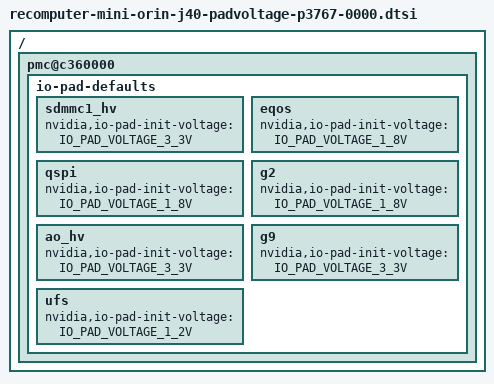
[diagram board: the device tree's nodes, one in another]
/*This dtsi file was generated by recomputer-mini-orin-j40.xlsm Revision: 1.04 */
/*
 * SPDX-FileCopyrightText: Copyright (c) 2022 NVIDIA CORPORATION & AFFILIATES. All rights reserved.
 * SPDX-License-Identifier: BSD-3-Clause
 *
 * Redistribution and use in source and binary forms, with or without
 * modification, are permitted provided that the following conditions are met:
 *
 * 1. Redistributions of source code must retain the above copyright notice, this
 * list of conditions and the following disclaimer.
 *
 * 2. Redistributions in binary form must reproduce the above copyright notice,
 * this list of conditions and the following disclaimer in the documentation
 * and/or other materials provided with the distribution.
 * 
 * 3. Neither the name of the copyright holder nor the names of its
 * contributors may be used to endorse or promote products derived from
 * this software without specific prior written permission.
 *
 * THIS SOFTWARE IS PROVIDED BY THE COPYRIGHT HOLDERS AND CONTRIBUTORS 'AS IS'
 * AND ANY EXPRESS OR IMPLIED WARRANTIES, INCLUDING, BUT NOT LIMITED TO, THE
 * IMPLIED WARRANTIES OF MERCHANTABILITY AND FITNESS FOR A PARTICULAR PURPOSE ARE
 * DISCLAIMED. IN NO EVENT SHALL THE COPYRIGHT HOLDER OR CONTRIBUTORS BE LIABLE
 * FOR ANY DIRECT, INDIRECT, INCIDENTAL, SPECIAL, EXEMPLARY, OR CONSEQUENTIAL
 * DAMAGES (INCLUDING, BUT NOT LIMITED TO, PROCUREMENT OF SUBSTITUTE GOODS OR
 * SERVICES; LOSS OF USE, DATA, OR PROFITS; OR BUSINESS INTERRUPTION) HOWEVER
 * CAUSED AND ON ANY THEORY OF LIABILITY, WHETHER IN CONTRACT, STRICT LIABILITY,
 * OR TORT (INCLUDING NEGLIGENCE OR OTHERWISE) ARISING IN ANY WAY OUT OF THE USE
 * OF THIS SOFTWARE, EVEN IF ADVISED OF THE POSSIBILITY OF SUCH DAMAGE.
 */

		#define IO_PAD_VOLTAGE_1_2V 1200000
		#define IO_PAD_VOLTAGE_1_8V 1800000
		#define IO_PAD_VOLTAGE_3_3V 3300000
/dts-v1/;
/ {
	pmc@c360000 {
		io-pad-defaults {
			sdmmc1_hv {
				nvidia,io-pad-init-voltage = <IO_PAD_VOLTAGE_3_3V>;
			};

			eqos {
				nvidia,io-pad-init-voltage = <IO_PAD_VOLTAGE_1_8V>;
			};

			qspi {
				nvidia,io-pad-init-voltage = <IO_PAD_VOLTAGE_1_8V>;
			};

			g2 {
				nvidia,io-pad-init-voltage = <IO_PAD_VOLTAGE_1_8V>;
			};

			ao_hv {
				nvidia,io-pad-init-voltage = <IO_PAD_VOLTAGE_3_3V>;
			};

			g9 {
				nvidia,io-pad-init-voltage = <IO_PAD_VOLTAGE_3_3V>;
			};

			ufs {
				nvidia,io-pad-init-voltage = <IO_PAD_VOLTAGE_1_2V>;
			};

		};
	};
};
